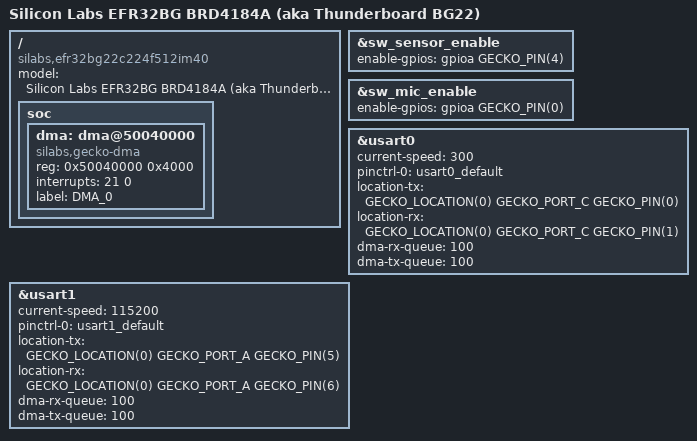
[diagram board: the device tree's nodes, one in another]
/*
 * Copyright (c) 2021 Sateesh Kotapati
 *
 * SPDX-License-Identifier: Apache-2.0
 */

/dts-v1/;
#include <silabs/efr32bg22.dtsi>
#include <silabs/efr32bg2x-pinctrl.dtsi>
#include "efr32bg22_brd4184.dtsi"

/ {
	model = "Silicon Labs EFR32BG BRD4184A (aka Thunderboard BG22)";
	compatible = "silabs,efr32bg22c224f512im40", "silabs,efr32bg_brd4184a",
		"silabs,efr32bg22";
          soc {
              dma: dma@50040000 {
                      compatible = "silabs,gecko-dma";
                      reg = <0x50040000 0x4000>;
                      interrupts = <21 0>;
                      label = "DMA_0";
                      #dma-cells = <2>;
              };
};
};

&sw_sensor_enable {
	enable-gpios = <&gpioa GECKO_PIN(4) GPIO_ACTIVE_HIGH>;
};

&sw_mic_enable {
	enable-gpios = <&gpioa GECKO_PIN(0) GPIO_ACTIVE_HIGH>;
};

&usart0 {
        status = "okay";
        current-speed = <300>;
        pinctrl-0 = <&usart0_default>;
        location-tx = <GECKO_LOCATION(0) GECKO_PORT_C GECKO_PIN(0)>;
        location-rx = <GECKO_LOCATION(0) GECKO_PORT_C GECKO_PIN(1)>;
        dma-rx-queue = <100>;
        dma-tx-queue = <100>;
};

&usart1 {
       status = "okay";
        current-speed = <115200>;
        pinctrl-0 = <&usart1_default>;
        location-tx = <GECKO_LOCATION(0) GECKO_PORT_A GECKO_PIN(5)>;
        location-rx = <GECKO_LOCATION(0) GECKO_PORT_A GECKO_PIN(6)>;
        dma-rx-queue = <100>;
        dma-tx-queue = <100>;
};
